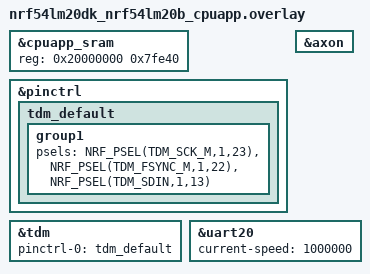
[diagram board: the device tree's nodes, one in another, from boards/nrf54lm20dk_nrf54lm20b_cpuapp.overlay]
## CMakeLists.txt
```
#
# Wake-word beamforming evaluation firmware.
# Based on 13_finalProto (nRF54LM20 DK, nRF Connect SDK / Zephyr, nRF Edge AI).
#
# Build from the Edge AI workspace, which is the only west topdir that contains
# the edge-ai module this model needs:
#
#   cd /Users/shreybae/Documents/iLAB/nrfedgeAI_workspace
#   west build -d /Users/shreybae/Documents/iLAB/nRF_SDK/14_ww_eval/build \
#        /Users/shreybae/Documents/iLAB/nRF_SDK/14_ww_eval \
#        --board nrf54lm20dk/nrf54lm20b/cpuapp --pristine
#
cmake_minimum_required(VERSION 3.20.0)

find_package(Zephyr REQUIRED HINTS $ENV{ZEPHYR_BASE})
project(ww_eval)

target_sources(app PRIVATE
  src/main.c
  src/audio_capture_adapter.c
  src/eval_paths.c
  src/beamformer_delay_sum.c
  src/audio_metrics.c
  src/wakeword_eval.c
  src/run_controller.c
  src/telemetry_protocol.c
  src/telemetry_transport.c
  src/command_interface.c
  src/nrf_edgeai_generated/nrf_edgeai_user_model.c
)

target_include_directories(app PRIVATE src)
```

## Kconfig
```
#
# Wake-word beamforming evaluation firmware
#

source "Kconfig.zephyr"

menu "Wakeword model post-processing (identical for every evaluation path)"

config WW_PROBABILITY_THRESHOLD
	int "Wakeword probability threshold (1/1000)"
	range 0 1000
	default 700
	help
	  A model window counts as positive when its class probability exceeds
	  this value divided by 1000. Runtime: set_threshold <0..1000>.

config WW_HISTORY_SIZE
	int "Size of wakeword predictions history"
	range 1 32
	default 6
	help
	  Number of most recent 10 ms model windows kept in the vote history.

config WW_COUNT_THRESHOLD
	int "Positive windows required within the history to confirm a detection"
	range 1 WW_HISTORY_SIZE
	default 4

config WW_COOLDOWN_MS
	int "Minimum time between two detections on the same path (ms)"
	default 1200
	help
	  Applied identically to every evaluation path so no path can collect
	  extra detections from a single utterance.

endmenu

menu "Evaluation paths and run defaults"

config EVAL_DEFAULT_PRESET
	string "Preset applied at boot and on 'reset'"
	default "raw_vs_bf_lr"
	help
	  One of: left right lr_mix bf_lr raw_3ch bf_3ch raw_vs_bf_lr raw_vs_bf_3ch full

config EVAL_DEFAULT_LIVE_PATH
	int "Path that receives live on-device inference during a run (0..5)"
	range 0 5
	default 3
	help
	  The wake-word runtime is a single stateful instance, so exactly one
	  path can be scored live. 0 raw_left, 1 raw_right, 2 raw_lr_mix,
	  3 bf_lr, 4 raw_3ch, 5 bf_3ch. Every other enabled path is scored by
	  replaying the recorded raw microphones through the device afterwards.

config EVAL_DEFAULT_DURATION_S
	int "Default run duration (s), 0 = until 'stop'"
	default 30

config EVAL_MAX_DELAY_SAMPLES
	int "Longest beamformer delay supported, in samples"
	range 1 256
	default 64
	help
	  At 16 kHz one sample is 62.5 us, or about 2.1 cm of path length.
	  64 samples covers 1.3 m, far more than any wearable array needs.

config EVAL_BF_LR_LEFT_DELAY
	int "BF_LR default left delay (samples)"
	default 0

config EVAL_BF_LR_RIGHT_DELAY
	int "BF_LR default right delay (samples)"
	default 0

config EVAL_BF_GAIN_Q15
	int "Default per-channel beamformer gain, Q15 (32767 = 1.0)"
	range 0 32767
	default 32767

config EVAL_CAPTURE_GAIN_SHIFT
	int "Extra digital gain from the mic's 24-bit domain, 6 dB per step"
	range 0 4
	default 0

config EVAL_FRAME_QUEUE_DEPTH
	int "Frames buffered between the capture thread and the evaluation thread"
	range 2 32
	default 8
	help
	  Each entry is one 16 ms stereo frame (1 KB). If the evaluation thread
	  falls behind, capture never blocks: the frame is dropped and counted.

config EVAL_TX_RING_BYTES
	int "Telemetry transmit ring buffer (bytes)"
	default 32768
	help
	  Audio and telemetry packets are staged here and drained by a
	  low-priority UART thread. Roughly 0.5 s of stereo audio at the default
	  size. When full, audio chunks are dropped and reported as AUDIO_GAP.

config EVAL_LINK_BYTES_PER_SEC
	int "Assumed usable link throughput for the admission check (bytes/s)"
	default 80000
	help
	  1 Mbaud is 100000 raw bytes/s; 80000 leaves margin for framing and
	  host jitter. Requests that would exceed this are rejected before a run
	  starts rather than dropping audio silently mid-run.

config EVAL_STATUS_PERIOD_MS
	int "Live STATUS / PATH_METRICS / AUDIO_STATS emission period (ms)"
	default 1000

config EVAL_TEXT_MODE_AT_BOOT
	bool "Start in human-readable text mode (binary framing enabled by the host tool)"
	default y

config EVAL_INFERENCE_DEADLINE_US
	int "Per-window inference deadline used for deadline-miss counting (us)"
	default 10000
	help
	  One model window is 10 ms of audio, so inference slower than this can
	  never keep up in real time.

endmenu
```

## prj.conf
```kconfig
# --- Audio capture (I2S/TDM, two INMP441 microphones) ---
CONFIG_I2S=y

# --- Serial telemetry link (uart20 = J-Link VCOM). Baud is set in the board
#     overlay. The link carries framed binary packets; Zephyr logging is routed
#     through the same framing by a custom backend (see telemetry_transport.c),
#     so the plain UART console and UART log backend are disabled on purpose.
CONFIG_SERIAL=y
CONFIG_UART_ASYNC_API=y
CONFIG_CONSOLE=n
CONFIG_UART_CONSOLE=n
CONFIG_LOG=y
CONFIG_LOG_MODE_DEFERRED=y
CONFIG_LOG_PROCESS_THREAD=y
CONFIG_LOG_PROCESS_THREAD_STACK_SIZE=2048
CONFIG_LOG_BUFFER_SIZE=8192
CONFIG_LOG_BACKEND_UART=n
CONFIG_LOG_BACKEND_RTT=n
CONFIG_LOG_DEFAULT_LEVEL=3
CONFIG_LOG_OUTPUT=y
CONFIG_CRC=y

# --- Threads ---
CONFIG_MAIN_STACK_SIZE=4096
CONFIG_SYSTEM_WORKQUEUE_STACK_SIZE=2048
CONFIG_HEAP_MEM_POOL_SIZE=0
CONFIG_THREAD_NAME=y
CONFIG_THREAD_RUNTIME_STATS=y
CONFIG_THREAD_STACK_INFO=y

# --- Buttons / LEDs (BTN1 start, BTN2 stop, LED1 run, LED2 detection) ---
CONFIG_GPIO=y
CONFIG_DK_LIBRARY=y

# --- nRF Edge AI wake-word runtime (same as 13_finalProto) ---
CONFIG_NRF_EDGEAI=y
CONFIG_NRF_AXON=y
CONFIG_NEWLIB_LIBC=y
CONFIG_FPU=y
CONFIG_NRF_AXON_INTERLAYER_BUFFER_SIZE=7000
CONFIG_NRF_AXON_PSUM_BUFFER_SIZE=0
CONFIG_NRF_SYS_EVENT=y

# --- Wake-word post-processing, identical for every path ---
CONFIG_WW_PROBABILITY_THRESHOLD=700
CONFIG_WW_HISTORY_SIZE=6
CONFIG_WW_COUNT_THRESHOLD=4
CONFIG_WW_COOLDOWN_MS=1200

# --- Evaluation defaults ---
CONFIG_EVAL_DEFAULT_PRESET="raw_vs_bf_lr"
CONFIG_EVAL_DEFAULT_LIVE_PATH=3
CONFIG_EVAL_DEFAULT_DURATION_S=30

# ring buffers larger than 32 KiB need this
CONFIG_RING_BUFFER=y
CONFIG_RING_BUFFER_LARGE=y
```

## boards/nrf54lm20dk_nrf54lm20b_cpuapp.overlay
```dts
/*
 * Copyright (c) 2026 Nordic Semiconductor ASA
 *
 * SPDX-License-Identifier: LicenseRef-Nordic-5-Clause
 */

 #include <dt-bindings/pinctrl/nrf-pinctrl.h>

&cpuapp_sram {
	reg = <0x20000000 0x7fe40>;
	ranges = <0x0 0x20000000 0x7fe40>;
};

&pinctrl {
	tdm_default: tdm_default {
		group1 {
			psels = <NRF_PSEL(TDM_SCK_M,1,23)>,
				<NRF_PSEL(TDM_FSYNC_M,1,22)>,
				<NRF_PSEL(TDM_SDIN,1,13)>;
		};
	};
};

&tdm {
	status = "okay";
	pinctrl-0 = <&tdm_default>;
	pinctrl-names = "default";
};

&axon {
	status = "okay";
};

/*
 * Telemetry link. uart20 is routed to the J-Link virtual COM port on the DK.
 * 1 Mbaud is the fastest rate the UARTE supports on this SoC; drop to 921600
 * if the host adapter cannot lock to it (see README, "link budget").
 */
&uart20 {
	current-speed = <1000000>;
};
```

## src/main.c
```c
/*
 * Wake-word beamforming evaluation firmware for the nRF54LM20 DK.
 *
 * Threads, highest priority first:
 *   audio_capture (6)  I2S DMA -> int16 L/R frames -> frame queue, never blocks
 *   eval          (7)  paths, metrics, live wake-word scoring, telemetry
 *   telemetry_rx  (8)  commands and replay audio from the host
 *   telemetry_tx (10)  drains the transmit ring over uart20
 *   main               10 ms housekeeping
 *
 * BTN1 starts a run with the current configuration, BTN2 stops it. Everything
 * else is driven over the serial link (see command_interface.c and README).
 */
#include <zephyr/kernel.h>
#include <zephyr/logging/log.h>
#include <dk_buttons_and_leds.h>

#include "audio_capture_adapter.h"
#include "command_interface.h"
#include "run_controller.h"
#include "telemetry_transport.h"
#include "wakeword_eval.h"

LOG_MODULE_REGISTER(main, LOG_LEVEL_INF);

static void button_changed(uint32_t state, uint32_t changed)
{
	uint32_t pressed = state & changed;

	if (pressed & DK_BTN1_MSK) {
		char err[120];

		if (run_controller_start(err, sizeof(err)) == 0) {
			LOG_INF("BTN1: start queued");
		} else {
			LOG_WRN("BTN1: start refused: %s", err);
		}
	}
	if (pressed & DK_BTN2_MSK) {
		if (run_controller_stop("button") == 0) {
			LOG_INF("BTN2: stop queued");
		} else {
			LOG_WRN("BTN2: nothing to stop");
		}
	}
}

int main(void)
{
	int err;

	err = dk_leds_init();
	if (err) {
		return err;
	}
	err = dk_buttons_init(button_changed);
	if (err) {
		return err;
	}

	err = tt_init();
	if (err) {
		/* Nothing else can report this; blink both LEDs forever. */
		for (;;) {
			dk_set_led_on(DK_LED1);
			dk_set_led_on(DK_LED2);
			k_sleep(K_MSEC(100));
			dk_set_led_off(DK_LED1);
			dk_set_led_off(DK_LED2);
			k_sleep(K_MSEC(100));
		}
	}
	command_interface_init();

	tt_send_text(TP_TEXT, "");
	tt_send_text(TP_TEXT, "=== wake-word beamforming evaluation (14_ww_eval) ===");
	tt_send_text(TP_TEXT, "type 'help' for commands, 'binary_mode on' for the dashboard");

	err = ww_eval_init();
	if (err) {
		LOG_ERR("wake-word runtime init failed: %d", err);
		tt_send_text(TP_ERROR, "err: wake-word runtime init failed (%d)", err);
		return err;
	}

	err = audio_capture_init();
	if (err) {
		LOG_ERR("capture init failed: %d", err);
		tt_send_text(TP_ERROR, "err: capture init failed (%d)", err);
		return err;
	}

	err = run_controller_init();
	if (err) {
		return err;
	}

	err = audio_capture_start();
	if (err) {
		LOG_ERR("capture start failed: %d", err);
		return err;
	}

	LOG_INF("ready: %u Hz, %u ch, %u-sample frames; BTN1 start, BTN2 stop",
		audio_capture_sample_rate_hz(), audio_capture_channels(),
		(unsigned)EVAL_FRAME_SAMPLES);
	run_controller_print_paths();

	for (;;) {
		run_controller_tick();
		k_sleep(K_MSEC(10));
	}
}
```

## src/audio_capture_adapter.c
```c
#include <errno.h>
#include <string.h>

#include <zephyr/device.h>
#include <zephyr/devicetree.h>
#include <zephyr/drivers/i2s.h>
#include <zephyr/kernel.h>
#include <zephyr/logging/log.h>
#include <zephyr/sys/atomic.h>
#include <zephyr/sys/util.h>

#include "audio_capture_adapter.h"

LOG_MODULE_REGISTER(capture, LOG_LEVEL_INF);

/*
 * Capture format, unchanged from 13_finalProto: the INMP441 emits 24-bit
 * samples left-justified in a 32-bit slot and needs 64 SCK per frame, so the
 * slot width stays at 32 bits (SCK = 16000 * 2 * 32 = 1.024 MHz).
 */
#define SAMPLE_RATE       EVAL_SAMPLE_RATE_HZ
#define SAMPLE_BIT_WIDTH  32
#define CHANNELS          2
#define BLOCK_PAIRS       EVAL_FRAME_SAMPLES
#define BLOCK_BYTES       (BLOCK_PAIRS * CHANNELS * sizeof(int32_t))
#define BLOCK_COUNT       4

#ifndef CONFIG_EVAL_CAPTURE_GAIN_SHIFT
#define CONFIG_EVAL_CAPTURE_GAIN_SHIFT 0
#endif
#ifndef CONFIG_EVAL_FRAME_QUEUE_DEPTH
#define CONFIG_EVAL_FRAME_QUEUE_DEPTH 8
#endif

#define TDM_NODE DT_NODELABEL(tdm)

#if !DT_NODE_HAS_STATUS(TDM_NODE, okay)
#error "TDM node is not enabled in the devicetree"
#endif

K_MEM_SLAB_DEFINE_IN_SECT_STATIC(rx_slab, __nocache, BLOCK_BYTES, BLOCK_COUNT, 4);
K_THREAD_STACK_DEFINE(capture_stack, 4096);
K_MSGQ_DEFINE(frame_queue, sizeof(struct capture_frame), CONFIG_EVAL_FRAME_QUEUE_DEPTH, 4);

static const struct device *const i2s = DEVICE_DT_GET(TDM_NODE);

static const struct i2s_config i2s_cfg = {
	.word_size = SAMPLE_BIT_WIDTH,
	.channels = CHANNELS,
	.format = I2S_FMT_DATA_FORMAT_I2S,
	.options = I2S_OPT_BIT_CLK_MASTER | I2S_OPT_FRAME_CLK_MASTER,
	.frame_clk_freq = SAMPLE_RATE,
	.mem_slab = &rx_slab,
	.block_size = BLOCK_BYTES,
	.timeout = 2000,
};

static struct k_thread capture_thread_data;
static atomic_t capture_active = ATOMIC_INIT(0);
static atomic_t enqueue_enabled = ATOMIC_INIT(1);
static struct audio_capture_stats stats;
static struct k_spinlock stats_lock;

/* The one frame being assembled; copied into the queue by value. */
static struct capture_frame work_frame;

static inline int16_t unpack(int32_t raw)
{
	/* 32-bit slot -> 24-bit sample -> 16-bit with optional gain, saturated. */
	int32_t s24 = raw >> 8;
	int32_t s = s24 >> (8 - CONFIG_EVAL_CAPTURE_GAIN_SHIFT);

	if (s > INT16_MAX) {
		return INT16_MAX;
	}
	if (s < INT16_MIN) {
		return INT16_MIN;
	}
	return (int16_t)s;
}

static void capture(void *a, void *b, void *c)
{
	ARG_UNUSED(a);
	ARG_UNUSED(b);
	ARG_UNUSED(c);

	int err = i2s_trigger(i2s, I2S_DIR_RX, I2S_TRIGGER_START);

	if (err) {
		LOG_ERR("I2S start failed: %d", err);
		atomic_clear(&capture_active);
		return;
	}

	LOG_INF("capture: %u Hz, %d ch, %d-bit slots, %u samples/frame (%u ms), queue %d",
		(unsigned)SAMPLE_RATE, CHANNELS, SAMPLE_BIT_WIDTH, (unsigned)BLOCK_PAIRS,
		(unsigned)EVAL_FRAME_MS, CONFIG_EVAL_FRAME_QUEUE_DEPTH);

	while (atomic_get(&capture_active)) {
		void *block;
		size_t bytes;

		err = i2s_read(i2s, &block, &bytes);
		if (err) {
			if (err != -EAGAIN) {
				k_spinlock_key_t key = k_spin_lock(&stats_lock);

				stats.i2s_errors++;
				k_spin_unlock(&stats_lock, key);
				LOG_WRN("I2S read failed: %d", err);
			}
			continue;
		}

		uint32_t t0 = k_cycle_get_32();
		const int32_t *stereo = block;
		size_t pairs = MIN(bytes / (CHANNELS * sizeof(int32_t)), (size_t)BLOCK_PAIRS);

		for (size_t i = 0; i < pairs; i++) {
			work_frame.left[i] = unpack(stereo[CHANNELS * i]);
			work_frame.right[i] = unpack(stereo[CHANNELS * i + 1]);
		}
		k_mem_slab_free(&rx_slab, block);

		work_frame.source = FRAME_SRC_CAPTURE;
		work_frame.channels = CHANNELS;
		work_frame.count = (uint16_t)pairs;

		uint32_t us = k_cyc_to_us_floor32(k_cycle_get_32() - t0);
		k_spinlock_key_t key = k_spin_lock(&stats_lock);

		work_frame.seq = stats.frames_captured++;
		stats.unpack_us_last = us;
		if (us > stats.unpack_us_max) {
			stats.unpack_us_max = us;
		}

		if (!atomic_get(&enqueue_enabled)) {
			stats.frames_discarded++;
			k_spin_unlock(&stats_lock, key);
			continue;
		}

		uint32_t used = k_msgq_num_used_get(&frame_queue);

		if (used > stats.queue_high_water) {
			stats.queue_high_water = used;
		}
		if (k_msgq_put(&frame_queue, &work_frame, K_NO_WAIT) != 0) {
			stats.frames_dropped++;
		}
		k_spin_unlock(&stats_lock, key);
	}

	i2s_trigger(i2s, I2S_DIR_RX, I2S_TRIGGER_DROP);
}

int audio_capture_init(void)
{
	if (!device_is_ready(i2s)) {
		return -ENODEV;
	}
	memset(&stats, 0, sizeof(stats));
	stats.queue_depth = CONFIG_EVAL_FRAME_QUEUE_DEPTH;
	return i2s_configure(i2s, I2S_DIR_RX, &i2s_cfg);
}

int audio_capture_start(void)
{
	if (!atomic_cas(&capture_active, 0, 1)) {
		return -EALREADY;
	}
	k_thread_create(&capture_thread_data, capture_stack, K_THREAD_STACK_SIZEOF(capture_stack),
			capture, NULL, NULL, NULL, 6, 0, K_NO_WAIT);
	k_thread_name_set(&capture_thread_data, "audio_capture");
	return 0;
}

struct k_msgq *audio_capture_queue(void)
{
	return &frame_queue;
}

void audio_capture_set_enqueue(bool enable)
{
	atomic_set(&enqueue_enabled, enable ? 1 : 0);
}

void audio_capture_get_stats(struct audio_capture_stats *out)
{
	k_spinlock_key_t key = k_spin_lock(&stats_lock);

	*out = stats;
	k_spin_unlock(&stats_lock, key);
}

void audio_capture_reset_stats(void)
{
	k_spinlock_key_t key = k_spin_lock(&stats_lock);
	uint32_t captured = stats.frames_captured;

	memset(&stats, 0, sizeof(stats));
	stats.frames_captured = captured;   /* keep the running frame counter monotonic */
	stats.queue_depth = CONFIG_EVAL_FRAME_QUEUE_DEPTH;
	k_spin_unlock(&stats_lock, key);
}

uint32_t audio_capture_sample_rate_hz(void)
{
	return SAMPLE_RATE;
}

uint8_t audio_capture_channels(void)
{
	return CHANNELS;
}
```

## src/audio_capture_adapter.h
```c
/*
 * Microphone capture: synchronized multi-channel I2S/TDM frames delivered to
 * the evaluation thread through a message queue. Capture never blocks on the
 * consumer; if the queue is full the frame is dropped and counted.
 *
 * Channel map (from boards/nrf54lm20dk_nrf54lm20b_cpuapp.overlay and the
 * INMP441 datasheet; confirm with the end-fire test in the README):
 *
 *   TDM slot 0 (WS low)  -> LEFT   INMP441 with its L/R pin tied to GND
 *   TDM slot 1 (WS high) -> RIGHT  INMP441 with its L/R pin tied to VDD
 *   pins: SCK P1.23, WS/FSYNC P1.22, SD P1.13
 *
 * Both microphones share one data line, so they are sampled by the same
 * clock edges: the pair is synchronized by construction. A third (center)
 * microphone cannot share this line; Phase 2 adds it on the PDM peripheral.
 */
#ifndef AUDIO_CAPTURE_ADAPTER_H_
#define AUDIO_CAPTURE_ADAPTER_H_

#include <stdbool.h>
#include <stdint.h>
#include <zephyr/kernel.h>

#include "eval_config.h"

enum frame_source {
	FRAME_SRC_CAPTURE = 0,   /* live microphones                      */
	FRAME_SRC_REPLAY = 1,    /* audio sent back by the host            */
	FRAME_SRC_STOP = 2,      /* marker: finish the current run in order */
	FRAME_SRC_REPLAY_END = 3,/* marker: finish the current replay pass  */
	FRAME_SRC_START = 4,     /* marker: open a run (bind runtime, reset) */
	FRAME_SRC_REPLAY_START = 5, /* marker: open a replay pass          */
};

struct capture_frame {
	uint32_t seq;            /* capture counter, or replay frame index */
	uint8_t source;          /* enum frame_source                      */
	uint8_t channels;        /* 2 today, 3 with a center microphone    */
	uint16_t count;          /* samples per channel                    */
	int16_t left[EVAL_FRAME_SAMPLES];
	int16_t right[EVAL_FRAME_SAMPLES];
	int16_t center[EVAL_FRAME_SAMPLES];
};

struct audio_capture_stats {
	uint32_t frames_captured;
	uint32_t frames_dropped;     /* queue full                          */
	uint32_t frames_discarded;   /* enqueue disabled (replay in progress) */
	uint32_t queue_high_water;
	uint32_t queue_depth;
	uint32_t i2s_errors;
	uint32_t unpack_us_last;
	uint32_t unpack_us_max;
};

int audio_capture_init(void);
int audio_capture_start(void);

struct k_msgq *audio_capture_queue(void);

/* When false, captured frames are discarded instead of queued (replay mode). */
void audio_capture_set_enqueue(bool enable);

void audio_capture_get_stats(struct audio_capture_stats *out);
void audio_capture_reset_stats(void);

uint32_t audio_capture_sample_rate_hz(void);
uint8_t audio_capture_channels(void);

#endif /* AUDIO_CAPTURE_ADAPTER_H_ */
```

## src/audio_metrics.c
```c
#include <string.h>

#include "audio_metrics.h"

void am_reset(struct audio_metrics *m)
{
	memset(m, 0, sizeof(*m));
}

static void accum(struct am_accum *a, const int16_t *s, size_t n)
{
	uint64_t sumsq = 0;
	uint16_t peak = a->peak_abs;
	uint32_t clips = 0;

	for (size_t i = 0; i < n; i++) {
		int32_t v = s[i];
		uint16_t mag = (uint16_t)((v < 0) ? -v : v);

		sumsq += (uint64_t)((int64_t)v * v);
		if (mag > peak) {
			peak = mag;
		}
		if (v >= INT16_MAX || v <= INT16_MIN) {
			clips++;
		}
	}
	a->sumsq += sumsq;
	a->samples += (uint32_t)n;
	a->peak_abs = peak;
	a->clips += clips;
}

void am_update(struct audio_metrics *m, const int16_t *samples, size_t n)
{
	accum(&m->run, samples, n);
	accum(&m->window, samples, n);
	m->crc32 = am_crc32_update(m->crc32, (const uint8_t *)samples, n * sizeof(int16_t));
	m->frames++;
}

void am_window_flush(struct audio_metrics *m, struct am_accum *out)
{
	*out = m->window;
	memset(&m->window, 0, sizeof(m->window));
}

uint32_t am_isqrt64(uint64_t x)
{
	uint64_t op = x;
	uint64_t res = 0;
	uint64_t one = 1ULL << 62;

	while (one > op) {
		one >>= 2;
	}
	while (one != 0U) {
		if (op >= (res + one)) {
			op -= res + one;
			res = (res >> 1) + one;
		} else {
			res >>= 1;
		}
		one >>= 2;
	}
	return (uint32_t)res;
}

uint32_t am_rms(const struct am_accum *a)
{
	if (a->samples == 0U) {
		return 0U;
	}
	return am_isqrt64(a->sumsq / a->samples);
}

/* Nibble-table CRC32, IEEE polynomial reflected (0xEDB88320): 64 bytes of table. */
static const uint32_t crc32_nib[16] = {
	0x00000000, 0x1DB71064, 0x3B6E20C8, 0x26D930AC, 0x76DC4190, 0x6B6B51F4, 0x4DB26158, 0x5005713C,
	0xEDB88320, 0xF00F9344, 0xD6D6A3E8, 0xCB61B38C, 0x9B64C2B0, 0x86D3D2D4, 0xA00AE278, 0xBDBDF21C,
};

uint32_t am_crc32_update(uint32_t crc, const uint8_t *data, size_t len)
{
	crc = ~crc;
	for (size_t i = 0; i < len; i++) {
		crc ^= data[i];
		crc = crc32_nib[crc & 0x0F] ^ (crc >> 4);
		crc = crc32_nib[crc & 0x0F] ^ (crc >> 4);
	}
	return ~crc;
}
```

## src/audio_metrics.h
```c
/*
 * Per-stream signal statistics: RMS, peak, clipping, and a running CRC32 of
 * every sample the stream produced. The CRC lets the host prove that its own
 * reconstruction of a processed path is bit-identical to what the device
 * computed, and lets a replay pass be checked against the live run.
 *
 * Two accumulators run side by side: "run" covers the whole run, "window"
 * covers the interval since the last am_window_flush() and feeds the periodic
 * AUDIO_STATS packets.
 *
 * Pure C, no Zephyr dependency.
 */
#ifndef AUDIO_METRICS_H_
#define AUDIO_METRICS_H_

#include <stddef.h>
#include <stdint.h>

#ifdef __cplusplus
extern "C" {
#endif

struct am_accum {
	uint64_t sumsq;
	uint32_t samples;
	uint16_t peak_abs;
	uint32_t clips;
};

struct audio_metrics {
	struct am_accum run;
	struct am_accum window;
	uint32_t crc32;
	uint32_t frames;
};

void am_reset(struct audio_metrics *m);
void am_update(struct audio_metrics *m, const int16_t *samples, size_t n);

/* Copies the window accumulator out and clears it. */
void am_window_flush(struct audio_metrics *m, struct am_accum *out);

uint32_t am_rms(const struct am_accum *a);

/* IEEE 802.3 CRC32 (same as zlib.crc32), incremental. Start with crc = 0. */
uint32_t am_crc32_update(uint32_t crc, const uint8_t *data, size_t len);

/* Integer square root of a 64-bit value (floor). */
uint32_t am_isqrt64(uint64_t x);

#ifdef __cplusplus
}
#endif

#endif /* AUDIO_METRICS_H_ */
```

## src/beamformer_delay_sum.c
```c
#include <string.h>

#include "beamformer_delay_sum.h"

void bf_init(struct bf_delay_sum *bf, uint8_t num_channels)
{
	memset(bf, 0, sizeof(*bf));
	if (num_channels < 1U) {
		num_channels = 1U;
	}
	if (num_channels > BF_MAX_CHANNELS) {
		num_channels = BF_MAX_CHANNELS;
	}
	bf->num_channels = num_channels;
	for (uint8_t c = 0; c < BF_MAX_CHANNELS; c++) {
		bf->gain_q15[c] = INT16_MAX;
	}
}

int bf_set_delays(struct bf_delay_sum *bf, const int16_t *delays, uint8_t count)
{
	if (count != bf->num_channels) {
		return -1;
	}
	for (uint8_t c = 0; c < count; c++) {
		if (delays[c] < 0 || delays[c] > BF_MAX_DELAY) {
			return -1;
		}
	}
	for (uint8_t c = 0; c < count; c++) {
		bf->delay[c] = (uint16_t)delays[c];
	}
	return 0;
}

int bf_set_gains(struct bf_delay_sum *bf, const int16_t *gains_q15, uint8_t count)
{
	if (count != bf->num_channels) {
		return -1;
	}
	for (uint8_t c = 0; c < count; c++) {
		if (gains_q15[c] < 0) {
			return -1;
		}
	}
	for (uint8_t c = 0; c < count; c++) {
		bf->gain_q15[c] = gains_q15[c];
	}
	return 0;
}

void bf_reset_history(struct bf_delay_sum *bf)
{
	for (uint8_t c = 0; c < BF_MAX_CHANNELS; c++) {
		memset(bf->ch[c].history, 0, sizeof(bf->ch[c].history));
		bf->ch[c].head = 0U;
	}
}

void bf_reset_stats(struct bf_delay_sum *bf)
{
	bf->clip_count = 0U;
	bf->frames_processed = 0U;
}

/*
 * Read x_c[n - delay] where n indexes the current frame. Samples earlier than
 * the frame come from the channel's history ring, which holds the last
 * BF_MAX_DELAY samples of the previous frames.
 */
static inline int32_t delayed_sample(const struct bf_channel_state *st, const int16_t *in,
				     size_t n, uint16_t delay)
{
	if (delay == 0U || n >= delay) {
		return in[n - delay];
	}
	/* Need a sample from before this frame: (delay - n) samples back in history. */
	uint16_t back = (uint16_t)(delay - n);
	uint16_t idx = (uint16_t)((st->head + BF_MAX_DELAY - back) % BF_MAX_DELAY);

	return st->history[idx];
}

static inline void push_history(struct bf_channel_state *st, const int16_t *in, size_t n)
{
	/* Keep only the tail of the frame; anything older is unreachable. */
	size_t start = (n > BF_MAX_DELAY) ? (n - BF_MAX_DELAY) : 0U;

	for (size_t i = start; i < n; i++) {
		st->history[st->head] = in[i];
		st->head = (uint16_t)((st->head + 1U) % BF_MAX_DELAY);
	}
}

void bf_process(struct bf_delay_sum *bf, const int16_t *const *inputs, size_t n, int16_t *out)
{
	const uint8_t nch = bf->num_channels;

	for (size_t i = 0; i < n; i++) {
		int32_t acc = 0;

		for (uint8_t c = 0; c < nch; c++) {
			int32_t s = delayed_sample(&bf->ch[c], inputs[c], i, bf->delay[c]);
			/* |s| <= 32768, gain <= 32767: product < 2^31, sum of 3 < 2^17 after shift. */
			acc += (s * (int32_t)bf->gain_q15[c]) >> 15;
		}

		/* Equal-weight average. Truncation toward zero, matching the host reference. */
		acc /= (int32_t)nch;

		int16_t y = bf_saturate_int16(acc);

		if (y == INT16_MAX || y == INT16_MIN) {
			bf->clip_count++;
		}
		out[i] = y;
	}

	for (uint8_t c = 0; c < nch; c++) {
		push_history(&bf->ch[c], inputs[c], n);
	}
	bf->frames_processed++;
}
```

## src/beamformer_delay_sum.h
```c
/*
 * Baseline integer delay-and-sum beamformer, 2 or 3 channels.
 *
 * This is deliberately the simplest spatial filter that has a steering
 * parameter: each channel is delayed by a whole number of samples, the
 * delayed channels are scaled by a Q15 gain, summed, divided by the channel
 * count, and saturated to int16. It is a controlled baseline for comparison,
 * not an adaptive or production beamformer.
 *
 * Sign convention
 * ---------------
 *   out[n] = sat16( ( sum_c  gain_c * x_c[n - delay_c] >> 15 ) / N )
 *
 * delay_c is how many samples channel c is held back before summing. To steer
 * toward a source whose wavefront reaches the LEFT microphone first by d
 * samples, delay the left channel: left_delay = d, right_delay = 0. With all
 * delays zero and unity gains the output is the plain average, which is what
 * 13_finalProto shipped as "beamform".
 *
 * Delay history carries across frame boundaries. At the start of a stream the
 * history is silence, so the first delay_c samples of a delayed channel read
 * as zero. bf_reset_history() must be called at the start of every run and
 * every replay pass so results do not depend on what came before.
 *
 * Pure C, no Zephyr dependency: compiled into the firmware and into the host
 * unit tests unchanged.
 */
#ifndef BEAMFORMER_DELAY_SUM_H_
#define BEAMFORMER_DELAY_SUM_H_

#include <stdbool.h>
#include <stddef.h>
#include <stdint.h>

#include "eval_config.h"

#ifdef __cplusplus
extern "C" {
#endif

#define BF_MAX_CHANNELS EVAL_MAX_CHANNELS
#define BF_MAX_DELAY    EVAL_MAX_DELAY_SAMPLES

struct bf_channel_state {
	int16_t history[BF_MAX_DELAY];
	uint16_t head;              /* next write position in history */
};

struct bf_delay_sum {
	uint8_t num_channels;
	uint16_t delay[BF_MAX_CHANNELS];
	int16_t gain_q15[BF_MAX_CHANNELS];
	struct bf_channel_state ch[BF_MAX_CHANNELS];
	uint32_t clip_count;        /* output samples that hit int16 limits  */
	uint32_t frames_processed;
};

/* Sets num_channels, zero delays, unity gains, empty history. */
void bf_init(struct bf_delay_sum *bf, uint8_t num_channels);

/* Returns -1 if any delay exceeds BF_MAX_DELAY or the channel count is wrong. */
int bf_set_delays(struct bf_delay_sum *bf, const int16_t *delays, uint8_t count);
int bf_set_gains(struct bf_delay_sum *bf, const int16_t *gains_q15, uint8_t count);

void bf_reset_history(struct bf_delay_sum *bf);
void bf_reset_stats(struct bf_delay_sum *bf);

/*
 * inputs[c] points at n samples of channel c. out receives n samples.
 * inputs and out must not overlap.
 */
void bf_process(struct bf_delay_sum *bf, const int16_t *const *inputs, size_t n, int16_t *out);

static inline int16_t bf_saturate_int16(int32_t x)
{
	if (x > INT16_MAX) {
		return INT16_MAX;
	}
	if (x < INT16_MIN) {
		return INT16_MIN;
	}
	return (int16_t)x;
}

#ifdef __cplusplus
}
#endif

#endif /* BEAMFORMER_DELAY_SUM_H_ */
```

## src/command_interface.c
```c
#include <ctype.h>
#include <errno.h>
#include <stdarg.h>
#include <stdio.h>
#include <stdlib.h>
#include <string.h>

#include <zephyr/kernel.h>
#include <zephyr/logging/log.h>

#include "command_interface.h"
#include "eval_config.h"
#include "run_controller.h"
#include "telemetry_transport.h"

LOG_MODULE_REGISTER(cmd, LOG_LEVEL_INF);

#define MAX_ARGS 8

static void ok(const char *fmt, ...) __attribute__((format(printf, 1, 2)));
static void fail(const char *fmt, ...) __attribute__((format(printf, 1, 2)));

static void ok(const char *fmt, ...)
{
	char buf[200];
	va_list ap;

	va_start(ap, fmt);
	vsnprintf(buf, sizeof(buf), fmt, ap);
	va_end(ap);
	tt_send_text(TP_ACK, "ok: %s", buf);
}

static void fail(const char *fmt, ...)
{
	char buf[200];
	va_list ap;

	va_start(ap, fmt);
	vsnprintf(buf, sizeof(buf), fmt, ap);
	va_end(ap);
	tt_send_text(TP_ACK, "err: %s", buf);
}

static const char *const help_lines[] = {
	"commands:",
	"  help | hello | status | config | list_paths | binary_mode on|off",
	"  start | stop | reset",
	"  enable <path> | disable <path> | enable_all | disable_all",
	"  set_preset left|right|lr_mix|bf_lr|raw_3ch|bf_3ch|raw_vs_bf_lr|raw_vs_bf_3ch|full",
	"  set_live_path <path>          path scored live during a run",
	"  set_duration <seconds>        0 = until stop",
	"  set_delay <path> <l> <r> <c>  integer samples, 0..max_delay",
	"  set_gain <path> <q15>         32767 = unity",
	"  set_threshold <0..1000|0.xx>  wake-word probability threshold",
	"  set_cooldown <ms>",
	"  set_capture <path|raw_left|raw_right|raw_center> on|off",
	"  set_capture_mode off|event_window|continuous_short|continuous_full",
	"  set_capture_seconds <s>",
	"  set_reduce center_only|lr_average|lc_average|rc_average|lrc_average",
	"  set_angle <deg> | set_distance <cm> | set_label <text> | set_phrase <text> | set_env <text>",
	"  replay_start <path> <frames> | replay_end",
	"  levels | levels on | levels off   raw microphone levels while idle (rig setup)",
	"paths: raw_left raw_right raw_lr_mix bf_lr raw_3ch bf_3ch",
};

static bool require_idle(void)
{
	if (!run_controller_config_mutable()) {
		fail("stop the run first");
		return false;
	}
	return true;
}

static int parse_path(const char *s)
{
	int p = eval_path_from_name(s);

	if (p < 0 && isdigit((unsigned char)s[0])) {
		p = atoi(s);
		if (p >= EVAL_PATH_COUNT) {
			p = -1;
		}
	}
	return p;
}

static bool parse_onoff(const char *s, bool *out)
{
	if (!strcmp(s, "on") || !strcmp(s, "1") || !strcmp(s, "true")) {
		*out = true;
		return true;
	}
	if (!strcmp(s, "off") || !strcmp(s, "0") || !strcmp(s, "false")) {
		*out = false;
		return true;
	}
	return false;
}

static void copy_rest(char *dst, size_t dst_len, int argc, char **argv, int from)
{
	dst[0] = '\0';
	for (int i = from; i < argc; i++) {
		size_t used = strlen(dst);

		if (used + strlen(argv[i]) + 2 > dst_len) {
			break;
		}
		if (used) {
			strcat(dst, "_");
		}
		strcat(dst, argv[i]);
	}
}

void command_interface_handle_line(const char *line_in)
{
	char line[256];
	char *argv[MAX_ARGS];
	int argc = 0;

	strncpy(line, line_in, sizeof(line) - 1);
	line[sizeof(line) - 1] = '\0';

	char *save = NULL;

	for (char *tok = strtok_r(line, " \t", &save); tok && argc < MAX_ARGS;
	     tok = strtok_r(NULL, " \t", &save)) {
		argv[argc++] = tok;
	}
	if (argc == 0) {
		return;
	}

	const char *cmd = argv[0];
	eval_run_config_t *cfg = run_controller_config();

	if (!strcmp(cmd, "help")) {
		for (size_t i = 0; i < ARRAY_SIZE(help_lines); i++) {
			tt_send_text(TP_TEXT, "%s", help_lines[i]);
		}
		ok("help");
	} else if (!strcmp(cmd, "hello")) {
		run_controller_emit_hello();
		ok("hello");
	} else if (!strcmp(cmd, "binary_mode")) {
		bool on;

		if (argc < 2 || !parse_onoff(argv[1], &on)) {
			fail("binary_mode on|off");
			return;
		}
		tt_set_binary_mode(on);
		ok("binary_mode %s", on ? "on" : "off");
		if (on) {
			run_controller_emit_hello();
			run_controller_emit_config();
		}
	} else if (!strcmp(cmd, "status")) {
		run_controller_emit_status();
		ok("status");
	} else if (!strcmp(cmd, "config")) {
		run_controller_emit_config();
		ok("config");
	} else if (!strcmp(cmd, "list_paths")) {
		run_controller_print_paths();
		ok("list_paths");
	} else if (!strcmp(cmd, "start")) {
		char err[160];
		int rc = run_controller_start(err, sizeof(err));

		if (rc) {
			fail("start: %s", err);
		} else {
			ok("start queued (%s)", err);
		}
	} else if (!strcmp(cmd, "stop")) {
		int rc = run_controller_stop("command");

		if (rc == -EALREADY) {
			fail("nothing running");
		} else if (rc) {
			fail("stop: %d", rc);
		} else {
			ok("stop queued");
		}
	} else if (!strcmp(cmd, "reset")) {
		if (!require_idle()) {
			return;
		}
		run_controller_reset();
		ok("reset to defaults (%s)", eval_preset_name(cfg->preset));
	} else if (!strcmp(cmd, "enable") || !strcmp(cmd, "disable")) {
		bool en = (cmd[0] == 'e');

		if (!require_idle()) {
			return;
		}
		if (argc < 2) {
			fail("%s <path>", cmd);
			return;
		}
		if (!strcmp(argv[1], "all")) {
			for (int p = 0; p < EVAL_PATH_COUNT; p++) {
				cfg->path[p].enabled = en;
			}
			ok("%s all", cmd);
			return;
		}
		int p = parse_path(argv[1]);

		if (p < 0) {
			fail("unknown path %s", argv[1]);
			return;
		}
		cfg->path[p].enabled = en;
		ok("%s %s", cmd, eval_path_name((eval_path_id_t)p));
	} else if (!strcmp(cmd, "enable_all") || !strcmp(cmd, "disable_all")) {
		if (!require_idle()) {
			return;
		}
		for (int p = 0; p < EVAL_PATH_COUNT; p++) {
			cfg->path[p].enabled = (cmd[0] == 'e');
		}
		ok("%s", cmd);
	} else if (!strcmp(cmd, "set_preset")) {
		if (!require_idle()) {
			return;
		}
		int pr = (argc >= 2) ? eval_preset_from_name(argv[1]) : -1;

		if (pr < 0) {
			fail("unknown preset");
			return;
		}
		eval_run_config_apply_preset(cfg, (eval_preset_t)pr);
		ok("preset %s, live path %s", eval_preset_name(cfg->preset),
		   eval_path_name(cfg->live_path));
	} else if (!strcmp(cmd, "set_live_path")) {
		if (!require_idle()) {
			return;
		}
		int p = (argc >= 2) ? parse_path(argv[1]) : -1;

		if (p < 0) {
			fail("unknown path");
			return;
		}
		cfg->live_path = (eval_path_id_t)p;
		cfg->path[p].enabled = true;
		ok("live path %s", eval_path_name((eval_path_id_t)p));
	} else if (!strcmp(cmd, "set_duration")) {
		if (!require_idle()) {
			return;
		}
		if (argc < 2) {
			fail("set_duration <seconds>");
			return;
		}
		cfg->duration_s = (uint16_t)atoi(argv[1]);
		ok("duration %u s", cfg->duration_s);
	} else if (!strcmp(cmd, "set_delay")) {
		if (!require_idle()) {
			return;
		}
		int p = (argc >= 4) ? parse_path(argv[1]) : -1;

		if (p < 0) {
			fail("set_delay <path> <left> <right> [center]");
			return;
		}
		int l = atoi(argv[2]), r = atoi(argv[3]), c = (argc >= 5) ? atoi(argv[4]) : 0;

		if (l < 0 || r < 0 || c < 0 || l > EVAL_MAX_DELAY_SAMPLES ||
		    r > EVAL_MAX_DELAY_SAMPLES || c > EVAL_MAX_DELAY_SAMPLES) {
			fail("delays must be 0..%d samples", (int)EVAL_MAX_DELAY_SAMPLES);
			return;
		}
		cfg->path[p].left_delay_samples = (int16_t)l;
		cfg->path[p].right_delay_samples = (int16_t)r;
		cfg->path[p].center_delay_samples = (int16_t)c;
		ok("%s delays l=%d r=%d c=%d", eval_path_name((eval_path_id_t)p), l, r, c);
	} else if (!strcmp(cmd, "set_gain")) {
		if (!require_idle()) {
			return;
		}
		int p = (argc >= 3) ? parse_path(argv[1]) : -1;
		int g = (argc >= 3) ? atoi(argv[2]) : -1;

		if (p < 0 || g < 0 || g > 32767) {
			fail("set_gain <path> <0..32767>");
			return;
		}
		cfg->path[p].gain_q15 = (int16_t)g;
		ok("%s gain %d", eval_path_name((eval_path_id_t)p), g);
	} else if (!strcmp(cmd, "set_threshold")) {
		if (!require_idle()) {
			return;
		}
		if (argc < 2) {
			fail("set_threshold <0..1000 or 0.xx>");
			return;
		}
		int v;

		if (strchr(argv[1], '.')) {
			v = (int)(strtod(argv[1], NULL) * 1000.0 + 0.5);
		} else {
			v = atoi(argv[1]);
		}
		if (v < 0 || v > 1000) {
			fail("threshold out of range");
			return;
		}
		cfg->ww_threshold_x1000 = (uint16_t)v;
		ok("threshold %u/1000", cfg->ww_threshold_x1000);
	} else if (!strcmp(cmd, "set_cooldown")) {
		if (!require_idle()) {
			return;
		}
		if (argc < 2) {
			fail("set_cooldown <ms>");
			return;
		}
		cfg->ww_cooldown_ms = (uint16_t)atoi(argv[1]);
		ok("cooldown %u ms", cfg->ww_cooldown_ms);
	} else if (!strcmp(cmd, "set_capture")) {
		if (!require_idle()) {
			return;
		}
		bool on;

		if (argc < 3 || !parse_onoff(argv[2], &on)) {
			fail("set_capture <path|raw_left|raw_right|raw_center> on|off");
			return;
		}
		/* raw_left / raw_right name the physical channels; the paths of the
		 * same name carry identical audio and are never streamed twice. */
		if (!strcmp(argv[1], "raw_center")) {
			cfg->capture_raw_center = on;
		} else if (!strcmp(argv[1], "raw_left")) {
			cfg->capture_raw_left = on;
		} else if (!strcmp(argv[1], "raw_right")) {
			cfg->capture_raw_right = on;
		} else {
			int p = parse_path(argv[1]);

			if (p < 0) {
				fail("unknown stream %s", argv[1]);
				return;
			}
			cfg->path[p].capture_audio = on;
		}
		char msg[160];
		uint32_t bps = 0;
		int rc = run_controller_admission_check(cfg, msg, sizeof(msg), &bps);

		ok("capture %s %s (%s%s)", argv[1], on ? "on" : "off", rc ? "WARNING " : "", msg);
	} else if (!strcmp(cmd, "set_capture_mode")) {
		if (!require_idle()) {
			return;
		}
		int m = (argc >= 2) ? eval_capture_mode_from_name(argv[1]) : -1;

		if (m < 0) {
			fail("set_capture_mode off|event_window|continuous_short|continuous_full");
			return;
		}
		cfg->capture_mode = (eval_capture_mode_t)m;
		ok("capture mode %s", eval_capture_mode_name(cfg->capture_mode));
	} else if (!strcmp(cmd, "set_capture_seconds")) {
		if (!require_idle()) {
			return;
		}
		if (argc < 2) {
			fail("set_capture_seconds <s>");
			return;
		}
		cfg->capture_seconds = (uint16_t)atoi(argv[1]);
		ok("capture seconds %u", cfg->capture_seconds);
	} else if (!strcmp(cmd, "set_reduce")) {
		if (!require_idle()) {
			return;
		}
		int m = -1;

		for (int i = 0; argc >= 2 && i < RAW_3CH_REDUCE_COUNT; i++) {
			if (!strcmp(argv[1], eval_reduce_mode_name((raw_3ch_reduce_mode_t)i))) {
				m = i;
			}
		}
		if (m < 0) {
			fail("set_reduce center_only|lr_average|lc_average|rc_average|lrc_average");
			return;
		}
		cfg->raw_3ch_reduce = (raw_3ch_reduce_mode_t)m;
		ok("raw_3ch reduce %s", eval_reduce_mode_name(cfg->raw_3ch_reduce));
	} else if (!strcmp(cmd, "set_angle")) {
		if (!require_idle() || argc < 2) {
			if (argc < 2) {
				fail("set_angle <deg>");
			}
			return;
		}
		cfg->angle_deg = (int16_t)atoi(argv[1]);
		ok("angle %d", cfg->angle_deg);
	} else if (!strcmp(cmd, "set_distance")) {
		if (!require_idle() || argc < 2) {
			if (argc < 2) {
				fail("set_distance <cm>");
			}
			return;
		}
		cfg->distance_cm = (uint16_t)atoi(argv[1]);
		ok("distance %u cm", cfg->distance_cm);
	} else if (!strcmp(cmd, "set_label") || !strcmp(cmd, "set_phrase") || !strcmp(cmd, "set_env")) {
		if (!require_idle()) {
			return;
		}
		if (argc < 2) {
			fail("%s <text>", cmd);
			return;
		}
		char *dst = (cmd[4] == 'l') ? cfg->label : (cmd[4] == 'p') ? cfg->phrase : cfg->environment;
		size_t cap = (cmd[4] == 'l') ? sizeof(cfg->label) :
			     (cmd[4] == 'p') ? sizeof(cfg->phrase) : sizeof(cfg->environment);

		copy_rest(dst, cap, argc, argv, 1);
		ok("%s %s", cmd + 4, dst);
	} else if (!strcmp(cmd, "levels")) {
		bool on = argc >= 2 && !strcmp(argv[1], "on");
		bool off = argc >= 2 && !strcmp(argv[1], "off");

		if (!run_controller_config_mutable()) {
			fail("levels are printed during a run already");
			return;
		}
		run_controller_request_levels(on, off);
		ok("levels %s", off ? "off" : on ? "every second (levels off to stop)" : "once");
	} else if (!strcmp(cmd, "replay_start")) {
		int p = (argc >= 3) ? parse_path(argv[1]) : -1;
		long frames = (argc >= 3) ? atol(argv[2]) : -1;
		char err[120];

		if (p < 0 || frames <= 0) {
			fail("replay_start <path> <frames>");
			return;
		}
		int rc = run_controller_replay_start((eval_path_id_t)p, (uint32_t)frames, err, sizeof(err));

		if (rc) {
			fail("replay_start: %s", err);
		} else {
			ok("replay queued");
		}
	} else if (!strcmp(cmd, "replay_end")) {
		int rc = run_controller_replay_end();

		if (rc) {
			fail("no replay in progress");
		} else {
			ok("replay_end queued");
		}
	} else {
		fail("unknown command '%s' (try help)", cmd);
	}
}

static void on_line(const char *line)
{
	command_interface_handle_line(line);
}

static void on_packet(const struct tp_header *h, const uint8_t *payload)
{
	run_controller_on_packet(h, payload);
}

void command_interface_init(void)
{
	tt_set_rx_callbacks(on_line, on_packet);
}
```

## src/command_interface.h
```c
/*
 * Line-oriented command interface. Lines arrive from the transport either as
 * plain text typed into a terminal or wrapped in TP_COMMAND packets by the
 * host tool; both reach command_interface_handle_line().
 *
 * Replies go out as TP_ACK text ("ok ..." / "err ...") so the host can match
 * them to the command it sent.
 */
#ifndef COMMAND_INTERFACE_H_
#define COMMAND_INTERFACE_H_

void command_interface_init(void);
void command_interface_handle_line(const char *line);

#endif /* COMMAND_INTERFACE_H_ */
```

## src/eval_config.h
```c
/*
 * Central configuration for the wake-word beamforming evaluation.
 *
 * Pure C: no Zephyr dependencies, so the DSP modules that include this header
 * can be compiled and unit-tested on a host machine (see tests_host/).
 */
#ifndef EVAL_CONFIG_H_
#define EVAL_CONFIG_H_

#include <stdbool.h>
#include <stddef.h>
#include <stdint.h>

#ifdef __cplusplus
extern "C" {
#endif

/* Capture geometry. Must match audio_capture_adapter.c and the wake-word model. */
#define EVAL_SAMPLE_RATE_HZ   16000U
#define EVAL_FRAME_SAMPLES    256U            /* one capture block, 16 ms */
#define EVAL_FRAME_MS         ((EVAL_FRAME_SAMPLES * 1000U) / EVAL_SAMPLE_RATE_HZ)
#define EVAL_MAX_CHANNELS     3U

#ifndef EVAL_MAX_DELAY_SAMPLES
#ifdef CONFIG_EVAL_MAX_DELAY_SAMPLES
#define EVAL_MAX_DELAY_SAMPLES CONFIG_EVAL_MAX_DELAY_SAMPLES
#else
#define EVAL_MAX_DELAY_SAMPLES 64
#endif
#endif

/*
 * Evaluation paths. The order is the wire order: stream/path ids in packets,
 * dashboard rows, and command names all use it.
 */
typedef enum {
	EVAL_PATH_RAW_LEFT = 0,
	EVAL_PATH_RAW_RIGHT,
	EVAL_PATH_RAW_LR_MIX,
	EVAL_PATH_BF_LR,
	EVAL_PATH_RAW_3CH,
	EVAL_PATH_BF_3CH,
	EVAL_PATH_COUNT
} eval_path_id_t;

/*
 * Physical microphone channels as captured. Packet stream ids for raw audio
 * use EVAL_STREAM_*; processed paths reuse their eval_path_id_t offset by
 * EVAL_STREAM_PATH_BASE so raw channels and paths never collide.
 */
typedef enum {
	EVAL_STREAM_RAW_LEFT = 0,
	EVAL_STREAM_RAW_RIGHT = 1,
	EVAL_STREAM_RAW_CENTER = 2,
	EVAL_STREAM_PATH_BASE = 16,   /* + eval_path_id_t */
	EVAL_STREAM_NONE = 0xFFFF,
} eval_stream_id_t;

#define EVAL_STREAM_FOR_PATH(p) ((uint16_t)(EVAL_STREAM_PATH_BASE + (p)))

typedef enum {
	RAW_3CH_CENTER_ONLY = 0,
	RAW_3CH_LR_AVERAGE,
	RAW_3CH_LC_AVERAGE,
	RAW_3CH_RC_AVERAGE,
	RAW_3CH_LRC_AVERAGE,
	RAW_3CH_REDUCE_COUNT
} raw_3ch_reduce_mode_t;

typedef enum {
	EVAL_PRESET_LEFT = 0,
	EVAL_PRESET_RIGHT,
	EVAL_PRESET_LR_MIX,
	EVAL_PRESET_BF_LR,
	EVAL_PRESET_RAW_3CH,
	EVAL_PRESET_BF_3CH,
	EVAL_PRESET_RAW_VS_BF_LR,
	EVAL_PRESET_RAW_VS_BF_3CH,
	EVAL_PRESET_FULL,
	EVAL_PRESET_COUNT
} eval_preset_t;

/*
 * What the device streams to the host during a run.
 *
 * The event-window and short-continuous policies are applied on the host:
 * the device streams the selected raw channels continuously and the host
 * keeps either everything, a window around each detection, or the first N
 * seconds. Keeping the policy on the host means no device RAM is spent on
 * multi-second rings and no burst has to be squeezed through the link.
 */
typedef enum {
	EVAL_CAPTURE_OFF = 0,
	EVAL_CAPTURE_EVENT_WINDOW,     /* host keeps +-N s around detections */
	EVAL_CAPTURE_CONTINUOUS_SHORT, /* host keeps the first N s            */
	EVAL_CAPTURE_CONTINUOUS_FULL,  /* host keeps the whole run            */
	EVAL_CAPTURE_MODE_COUNT
} eval_capture_mode_t;

typedef struct {
	eval_path_id_t id;
	const char *name;
	bool enabled;
	bool capture_audio;      /* stream this path's processed audio live   */
	bool run_wakeword;       /* score this path (live if it is the live path,
				    otherwise by replay)                       */
	int16_t left_delay_samples;
	int16_t right_delay_samples;
	int16_t center_delay_samples;
	int16_t gain_q15;        /* per-path output gain, 32767 = unity        */
} eval_path_config_t;

typedef struct {
	eval_path_config_t path[EVAL_PATH_COUNT];
	eval_path_id_t live_path;
	eval_preset_t preset;
	raw_3ch_reduce_mode_t raw_3ch_reduce;
	eval_capture_mode_t capture_mode;
	uint16_t capture_seconds;     /* CONTINUOUS_SHORT length / window half-size */
	bool capture_raw_left;
	bool capture_raw_right;
	bool capture_raw_center;
	uint16_t duration_s;          /* 0 = until stop */
	uint16_t ww_threshold_x1000;
	uint16_t ww_cooldown_ms;
	int16_t angle_deg;
	uint16_t distance_cm;
	char label[48];
	char phrase[32];
	char environment[32];
} eval_run_config_t;

const char *eval_path_name(eval_path_id_t id);
const char *eval_preset_name(eval_preset_t p);
const char *eval_capture_mode_name(eval_capture_mode_t m);
const char *eval_reduce_mode_name(raw_3ch_reduce_mode_t m);
int eval_path_from_name(const char *name);        /* -1 if unknown */
int eval_preset_from_name(const char *name);      /* -1 if unknown */
int eval_capture_mode_from_name(const char *name);

void eval_run_config_defaults(eval_run_config_t *cfg);
void eval_run_config_apply_preset(eval_run_config_t *cfg, eval_preset_t preset);
uint32_t eval_run_config_enabled_mask(const eval_run_config_t *cfg);

#ifdef __cplusplus
}
#endif

#endif /* EVAL_CONFIG_H_ */
```

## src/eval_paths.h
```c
/*
 * Generates every enabled evaluation path from one synchronized microphone
 * frame, so all paths see exactly the same instant of sound.
 *
 *   RAW_LEFT     out[n] = left[n]
 *   RAW_RIGHT    out[n] = right[n]
 *   RAW_LR_MIX   out[n] = left[n]/2 + right[n]/2         (overflow-safe average)
 *   BF_LR        baseline integer delay-and-sum of left and right
 *   RAW_3CH      configurable reduction of left/right/center to mono
 *   BF_3CH       baseline 3-channel integer delay-and-sum, center is reference
 *
 * Integer division here truncates toward zero, and tools/dsp_reference.py
 * mirrors that exactly so the host can reproduce and verify every path.
 *
 * Pure C, no Zephyr dependency.
 */
#ifndef EVAL_PATHS_H_
#define EVAL_PATHS_H_

#include <stdbool.h>
#include <stddef.h>
#include <stdint.h>

#include "beamformer_delay_sum.h"
#include "eval_config.h"

#ifdef __cplusplus
extern "C" {
#endif

struct eval_frame {
	uint32_t seq;            /* capture frame counter                       */
	uint32_t sample_index;   /* index of the first sample since run start   */
	uint16_t count;          /* samples per channel, EVAL_FRAME_SAMPLES     */
	const int16_t *left;
	const int16_t *right;
	const int16_t *center;   /* NULL when no third microphone is captured   */
};

struct eval_paths {
	const eval_run_config_t *cfg;
	struct bf_delay_sum bf_lr;
	struct bf_delay_sum bf_3ch;
	int16_t out[EVAL_PATH_COUNT][EVAL_FRAME_SAMPLES];
	uint32_t produced_mask;  /* paths filled by the last eval_paths_process */
	uint32_t unavailable_mask; /* enabled paths that could not be produced  */
	uint32_t mix_clips;      /* RAW_3CH reductions never clip; kept for symmetry */
};

void eval_paths_init(struct eval_paths *ep, const eval_run_config_t *cfg);

/* Pushes the configured delays and gains into the beamformers. Returns -1 if
 * any delay is out of range. */
int eval_paths_apply_config(struct eval_paths *ep);

/* Clears delay histories; call at the start of every run and replay pass. */
void eval_paths_reset_state(struct eval_paths *ep);

/* Fills ep->out for every enabled path. Returns the produced bitmask. */
uint32_t eval_paths_process(struct eval_paths *ep, const struct eval_frame *f);

static inline const int16_t *eval_paths_output(const struct eval_paths *ep, eval_path_id_t id)
{
	return ep->out[id];
}

#ifdef __cplusplus
}
#endif

#endif /* EVAL_PATHS_H_ */
```
